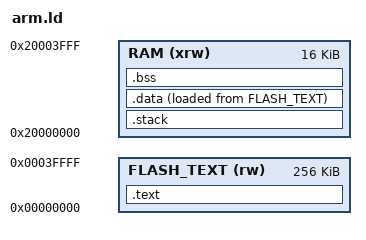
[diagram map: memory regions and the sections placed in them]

MEMORY
{
    FLASH_TEXT (rw) : ORIGIN = 0x00000000, LENGTH = 256K /* .text */
    RAM (xrw)       : ORIGIN = 0x20000000, LENGTH = 16K
}

_stack_size = 2K;

/* define output sections */
SECTIONS
{
    /* The program code and other data goes into FLASH */
    .text :
    {
        _stext = .;
        . = ALIGN(4);
        KEEP(*(.isr_vector))
        *(.text)           /* .text sections (code) */
        *(.text*)          /* .text* sections (code) */
        *(.rodata)         /* .rodata sections (constants, strings, etc.) */
        *(.rodata*)        /* .rodata* sections (constants, strings, etc.) */
        . = ALIGN(4);
        _etext = .;        /* define a global symbol at end of code */
    } >FLASH_TEXT

    /* Put the stack at the bottom of RAM, so that the application will
     * crash on stack overflow instead of silently corrupting memory.
     * See: http://blog.japaric.io/stack-overflow-protection/ */
    .stack :
    {
        . = ALIGN(4);
        . += _stack_size;
        __StackTop = .;
    } >RAM

    /* This is the initialized data section
    The program executes knowing that the data is in the RAM
    but the loader puts the initial values in the FLASH (inidata).
    It is one task of the startup to copy the initial values from FLASH to RAM. */
    .data :
    {
        . = ALIGN(4);
        _sdata = .;        /* create a global symbol at data start; used by startup code in order to initialise the .data section in RAM */
        *(.data)           /* .data sections */
        *(.data*)          /* .data* sections */

        . = ALIGN(4);
        _edata = .;        /* define a global symbol at data end; used by startup code in order to initialise the .data section in RAM */
    } >RAM AT>FLASH_TEXT

    /* Uninitialized data section */
    .bss :
    {
        . = ALIGN(4);
        _sbss = .;         /* define a global symbol at bss start; used by startup code */
        *(.bss)
        *(.bss*)
        *(COMMON)

        . = ALIGN(4);
        _ebss = .;         /* define a global symbol at bss end; used by startup code and GC */
    } >RAM

    /DISCARD/ :
    {
        *(.ARM.exidx.*)
        *(.ARM.attributes)
        *(.stack) /* from nrfx */
        *(.heap)  /* from nrfx */
    }
}

/* For the nrfx startup file. */
__etext = _etext;
__data_start__ = _sdata;
__bss_start__ = _sbss;

/* For the memory allocator. */
_heap_start = _ebss;
_heap_end = ORIGIN(RAM) + LENGTH(RAM);
runtime.heapptr = _heap_start; /* necessary? */
